# GD32H75E register map
File version: 1.0
CPU: CM7 r1p2, little endian, MPU, FPU, 4 interrupt priority bits
Registers are 32-bit, read-write, reset 0x0 unless marked. A register's access mark holds for its fields unless they carry their own. Offsets are from the block's base; [hi:lo] are bit positions; {n}, {i} and the like mark numbered series.

## DAC — Digital-to-analog converter
Base 0x40007400
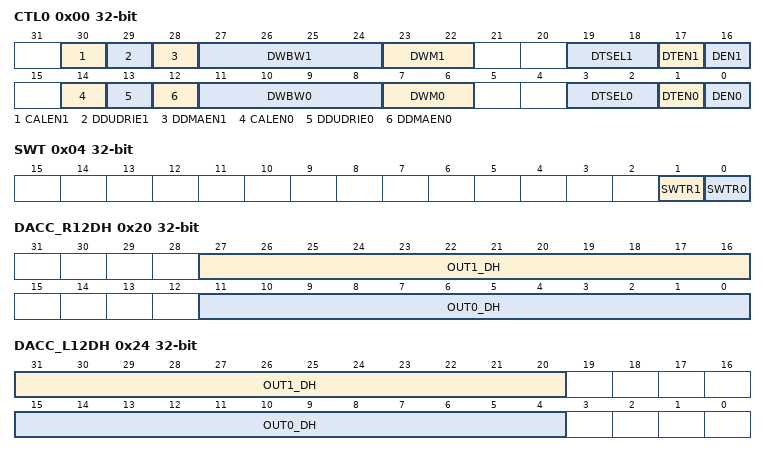
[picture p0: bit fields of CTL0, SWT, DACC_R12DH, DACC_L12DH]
0x00 CTL0 — Control register 0
  [30] CALEN1 — DAC_OUT1 calibration enable
  [29] DDUDRIE1 — DAC_OUT1 DMA underrun interrupt enable
  [28] DDMAEN1 — DAC_OUT1 DMA enable
  [27:24] DWBW1 — DAC_OUT1 noise wave bit width
  [23:22] DWM1 — DAC_OUT1 noise wave mode
  [19:18] DTSEL1 — DAC_OUT1 trigger selection
  [17] DTEN1 — DAC_OUT1 trigger enable
  [16] DEN1 — DAC_OUT1 enable
  [14] CALEN0 — DAC_OUT0 calibration enable
  [13] DDUDRIE0 — DAC_OUT0 DMA underrun interrupt enable
  [12] DDMAEN0 — DAC_OUT0 DMA enable
  [11:8] DWBW0 — DAC_OUT0 noise wave bit width
  [7:6] DWM0 — DAC_OUT0 noise wave mode
  [3:2] DTSEL0 — DAC_OUT0 trigger selection
  [1] DTEN0 — DAC_OUT0 trigger enable
  [0] DEN0 — DAC_OUT0 enable
0x04 SWT wo — Software trigger register
  [1] SWTR1 — DAC_OUT1 software trigger, cleared by hardware
  [0] SWTR0 — DAC_OUT0 software trigger, cleared by hardware
0x08 OUT0_R12DH — DAC_OUT0 12-bit right-aligned data holding register
  [11:0] OUT0_DH — DAC_OUT0 12-bit right-aligned data
0x0C OUT0_L12DH — DAC_OUT0 12-bit left-aligned data holding register
  [15:4] OUT0_DH — DAC_OUT0 12-bit left-aligned data
0x10 OUT0_R8DH — DAC_OUT0 8-bit right-aligned data holding register
  [7:0] OUT0_DH — DAC_OUT0 8-bit right-aligned data
0x14 OUT1_R12DH — DAC_OUT1 12-bit right-aligned data holding register
  [11:0] OUT1_DH — DAC_OUT1 12-bit right-aligned data
0x18 OUT1_L12DH — DAC_OUT1 12-bit left-aligned data holding register
  [15:4] OUT1_DH — OUT1_DH[11:0]
0x1C OUT1_R8DH — DAC_OUT1 8-bit right-aligned data holding register
  [7:0] OUT1_DH — DAC_OUT1 8-bit right-aligned data
0x20 DACC_R12DH — DAC concurrent mode 12-bit right-aligned data holding register
  [27:16] OUT1_DH — DAC_OUT1 12-bit right-aligned data
  [11:0] OUT0_DH — DAC_OUT0 12-bit right-aligned data
0x24 DACC_L12DH — DAC concurrent mode 12-bit left-aligned data holding register
  [31:20] OUT1_DH — DAC_OUT1 12-bit left-aligned data
  [15:4] OUT0_DH — DAC_OUT0 12-bit left-aligned data
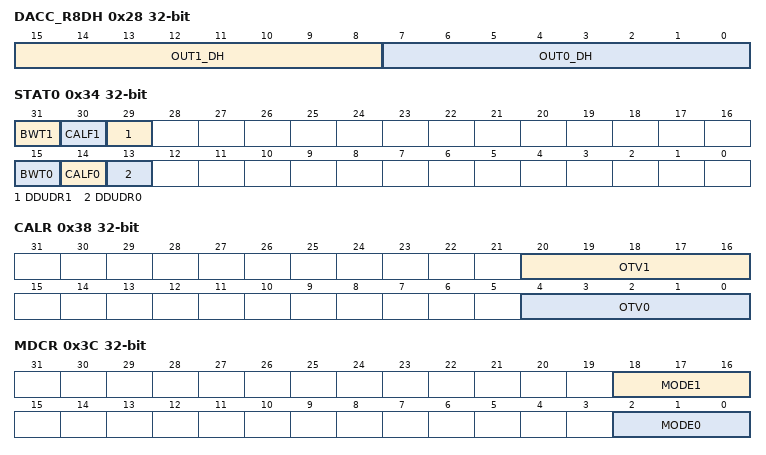
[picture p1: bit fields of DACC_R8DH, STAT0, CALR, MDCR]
0x28 DACC_R8DH — DAC concurrent mode 8-bit right-aligned data holding register
  [15:8] OUT1_DH — DAC_OUT1 8-bit right-aligned data
  [7:0] OUT0_DH — DAC_OUT0 8-bit right-aligned data
0x2C OUT0_DO ro — DAC_OUT0 data output register
  [11:0] OUT0_DO — DAC_OUT0 data output
0x30 OUT1_DO ro — DAC_OUT1 data output register
  [11:0] OUT1_DO — DAC_OUT1 data output
0x34 STAT0 ro — DAC Status register 0
  [31] BWT1 — This bit will be set after sample and keep mode enable
  [30] CALF1 — DAC_OUT1 calibration offset flag
  [29] DDUDR1 — DAC_OUT1 DMA underrun flag, set by hardware, cleared by software write 1
  [15] BWT0 — This bit will be set after sample and keep mode enable
  [14] CALF0 — DAC_OUT0 calibration offset flag
  [13] DDUDR0 — DAC_OUT0 DMA underrun flag, set by hardware, cleared by software write 1
0x38 CALR — DAC calibration Register 1
  [20:16] OTV1 — DAC_OUT1 offset calibration value
  [4:0] OTV0 — DAC_OUT0 offset calibration value
0x3C MDCR — DAC mode control Register 1
  [18:16] MODE1 — DAC OUT1 mode.
  [2:0] MODE0 — DAC OUT0 mode.
0x40 SKSTR0 — DAC sample and keep sample time Register 0
  [9:0] TSAMP0 — DAC_OUT0 sample time.
0x44 SKSTR1 — DAC sample and keep sample time Register 1
  [9:0] TSAMP1 — DAC_OUT refresh time (only valid in Sample and hold mode)
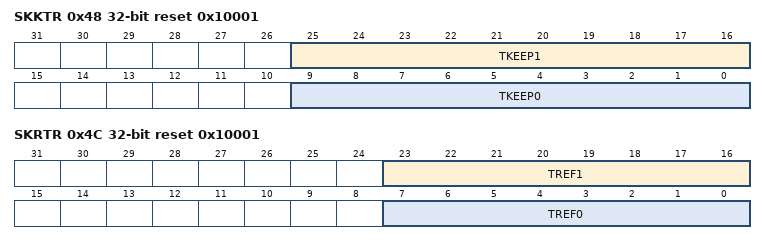
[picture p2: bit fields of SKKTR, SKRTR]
0x48 SKKTR reset 0x10001 — DAC sample and keep keep time Register
  [25:16] TKEEP1 — DAC_OUT1 keep time
  [9:0] TKEEP0 — DAC_OUT0 keep time
0x4C SKRTR reset 0x10001 — DAC sample and keep refresh time Register
  [23:16] TREF1 — DAC_OUT1 refresh time
  [7:0] TREF0 — DAC_OUT0 refresh time

## DMAMUX — DMA request multiplexer
Base 0x40020800
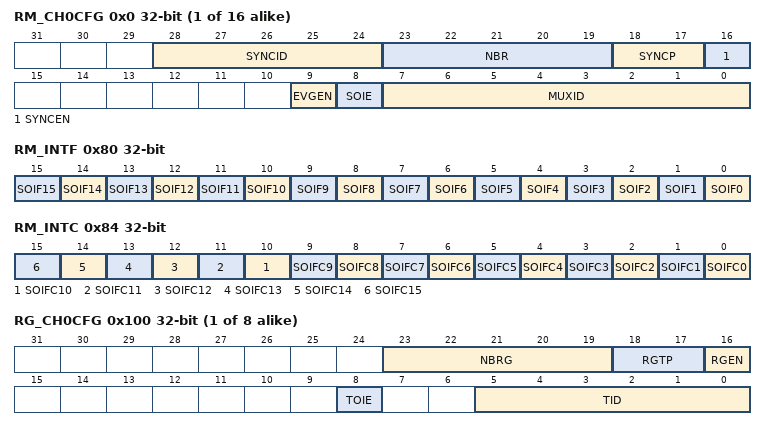
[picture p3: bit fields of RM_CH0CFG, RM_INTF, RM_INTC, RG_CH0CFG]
{0x0+4i} RM_CH{i}CFG (i=0..15) — Request multiplexer channel {i} configuration regist
  [28:24] SYNCID — Synchronization input identification
  [23:19] NBR — Number of DMA requests to forward
  [18:17] SYNCP — Synchronization input polarity
  [16] SYNCEN — Synchronization enable
  [9] EVGEN — Event generation enable
  [8] SOIE — Synchronization overrun interrupt enable
  [7:0] MUXID — Multiplexer input identification
0x80 RM_INTF ro — Request multiplexer channel interrupt flag register
  [n] SOIF{n} (n=0..15) — Synchronization overrun event flag of request multiplexer channel {n}
0x84 RM_INTC wo — Request multiplexer channel interrupt flag clear register
  [n] SOIFC{n} (n=0..15) — Clear bit for synchronization overrun event flag of request multiplexer channel {n}
{0x100+4i} RG_CH{i}CFG (i=0..7) — Request generator channel {i} configuration regist
  [23:19] NBRG — Number of DMA requests to be generated
  [18:17] RGTP — DMAMUX request generator trigger polarity
  [16] RGEN — DMAMUX request generator channel x enable
  [8] TOIE — Trigger overrun interrupt enable
  [5:0] TID — Trigger input identification
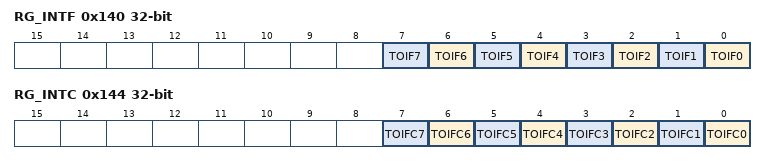
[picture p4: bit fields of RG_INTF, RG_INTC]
0x140 RG_INTF ro — Request generator channel interrupt flag register
  [n] TOIF{n} (n=0..7) — Trigger overrun event flag of request generator channel {n}
0x144 RG_INTC wo — Rquest generator channel interrupt flag clear register
  [n] TOIFC{n} (n=0..7) — Clear bit for trigger overrun event flag of request generator channel {n}
